# HK32F0301M register map
Vendor: HKMicroChip Ltd.; Series: HK32F0301M; File version: 1.0
CPU: CM0 r0p0, little endian, no MPU, no FPU, 3 interrupt priority bits
Registers are 32-bit, read-write, reset 0x0 unless marked. A register's access mark holds for its fields unless they carry their own. Offsets are from the block's base; [hi:lo] are bit positions.

## IOMUX
Base 0x40017C00
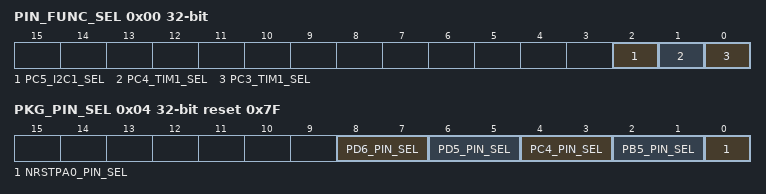
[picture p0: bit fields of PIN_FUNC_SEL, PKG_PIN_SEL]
0x00 PIN_FUNC_SEL — PIN function select register
  [2] PC5_I2C1_SEL — I2C1 pin select
  [1] PC4_TIM1_SEL — timer1 pin select
  [0] PC3_TIM1_SEL — timer1 pin select
0x04 PKG_PIN_SEL reset 0x7F
  [8:7] PD6_PIN_SEL
  [6:5] PD5_PIN_SEL
  [4:3] PC4_PIN_SEL
  [2:1] PB5_PIN_SEL
  [0] NRSTPA0_PIN_SEL — NRST PA0 function select
0x08 NRST_PIN_KEY
  [14:0] NRST_PIN_KEY
0x0C NRST_PA0_SEL
  [0] NRST_PA0_SEL
0x10 TIM2_CH0_IN_SEL
  [1:0] TIM2_CH0_IN_SEL

## SPI — Serial peripheral interface
Base 0x40013000
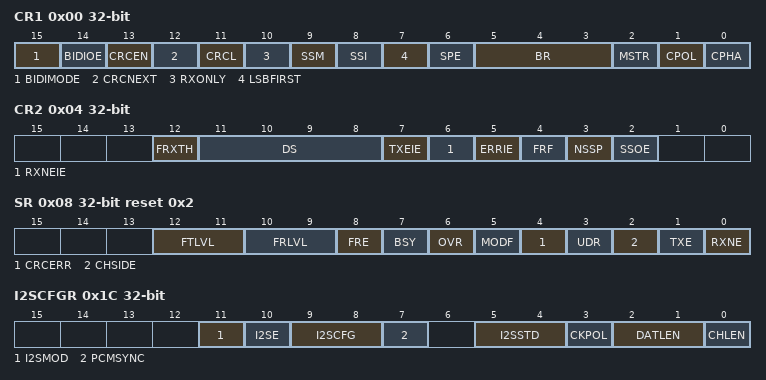
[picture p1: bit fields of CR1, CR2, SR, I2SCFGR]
0x00 CR1 — control register 1
  [15] BIDIMODE — Bidirectional data mode enable
  [14] BIDIOE — Output enable in bidirectional mode
  [13] CRCEN — Hardware CRC calculation enable
  [12] CRCNEXT — CRC transfer next
  [11] CRCL — CRC lenth
  [10] RXONLY — Receive only
  [9] SSM — Software slave management
  [8] SSI — Internal slave select
  [7] LSBFIRST — Frame format
  [6] SPE — SPI enable
  [5:3] BR — Baud rate control
  [2] MSTR — Master selection
  [1] CPOL — Clock polarity
  [0] CPHA — Clock phase
0x04 CR2 — control register 2
  [12] FRXTH — FIFO reception threshold
  [11:8] DS — Data size
  [7] TXEIE — Tx buffer empty interrupt enable
  [6] RXNEIE — RX buffer not empty interrupt enable
  [5] ERRIE — Error interrupt enable
  [4] FRF — Frame format
  [3] NSSP — NSS pulse management
  [2] SSOE — SS output enable
0x08 SR access per field reset 0x2 — status register
  [12:11] FTLVL ro — FIFO transmission level
  [10:9] FRLVL ro — FIFO reception level
  [8] FRE ro — frame format error
  [7] BSY ro — Busy flag
  [6] OVR ro — Overrun flag
  [5] MODF ro — Mode fault
  [4] CRCERR rw — CRC error flag
  [3] UDR ro — Underrun flag
  [2] CHSIDE ro — Channel side
  [1] TXE ro — Transmit buffer empty
  [0] RXNE ro — Receive buffer not empty
0x0C DR — data register
  [15:0] DR — Data register
0x10 CRCPR reset 0x7 — CRC polynomial register
  [15:0] CRCPOLY
0x14 RXCRCR ro — RX CRC register
  [15:0] RxCRC
0x18 TXCRCR ro — TX CRC register
  [15:0] TxCRC
0x1C I2SCFGR — I2S configuration register
  [11] I2SMOD — I2S mode selection
  [10] I2SE — I2S Enable
  [9:8] I2SCFG — I2S configuration mode
  [7] PCMSYNC — PCM frame synchronization
  [5:4] I2SSTD — I2S standard selection
  [3] CKPOL — Steady state clock polarity
  [2:1] DATLEN — Data length to be transferred
  [0] CHLEN — Channel length (number of bits per audio channel)
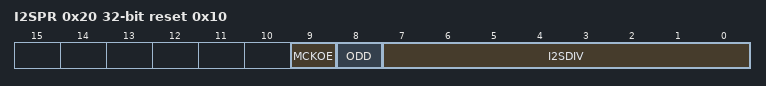
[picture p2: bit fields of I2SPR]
0x20 I2SPR reset 0x10 — I2S prescaler register
  [9] MCKOE — Master clock output enable
  [8] ODD — Odd factor for the prescaler
  [7:0] I2SDIV — I2S Linear prescaler

## PWR — Power control
Base 0x40007000
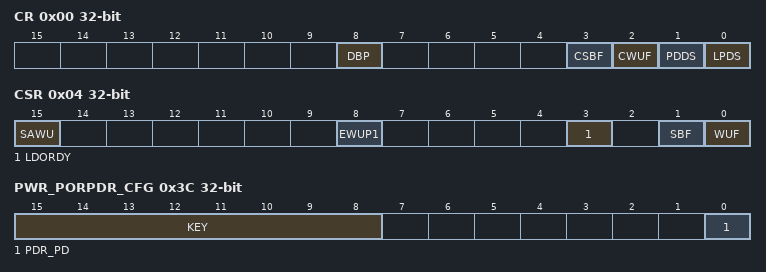
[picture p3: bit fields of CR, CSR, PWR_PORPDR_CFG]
0x00 CR — power control register
  [8] DBP — Disable backup domain write protection
  [3] CSBF — Clear standby flag
  [2] CWUF — Clear wakeup flag
  [1] PDDS — Power down deepsleep
  [0] LPDS — Low-power deep sleep
0x04 CSR access per field — power control/status register
  [15] SAWU rw — Enable standby wakeup
  [8] EWUP1 rw — Enable WKUP pin 1
  [3] LDORDY ro — LDO status
  [1] SBF ro — Standby flag
  [0] WUF ro — Wakeup flag
0x34 PWR_WUP_POL — power wakeup polarity register
  [0] WUPOL1 — WKUP1 polarity
0x3C PWR_PORPDR_CFG access per field — power PDR register
  [15:8] KEY wo
  [0] PDR_PD rw — PDR power down
0x9C PWR_SAWUT reset 0x7D — standby wakeup timer
  [15:0] TIME_CNT
0xA0 PWR_SBKP0 — standby backup0
  [15:0] SBKP0
0xA4 PWR_SBKP1 — standby backup1
  [15:0] SBKP1

## IWDG — Independent watchdog
Base 0x40003000
0x00 KR wo — Key register
  [15:0] KEY — Key value
0x04 PR — Prescaler register
  [2:0] PR — Prescaler divider
0x08 RLR reset 0xFFF — Reload register
  [11:0] RL — Watchdog counter reload value
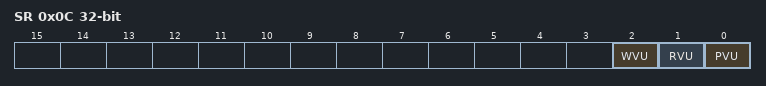
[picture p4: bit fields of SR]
0x0C SR ro — Status register
  [2] WVU — Watchdog counter window value update
  [1] RVU — Watchdog counter reload value update
  [0] PVU — Watchdog prescaler value update
0x10 WINR reset 0xFFF — Window register
  [11:0] WIN — Watchdog counter window value
